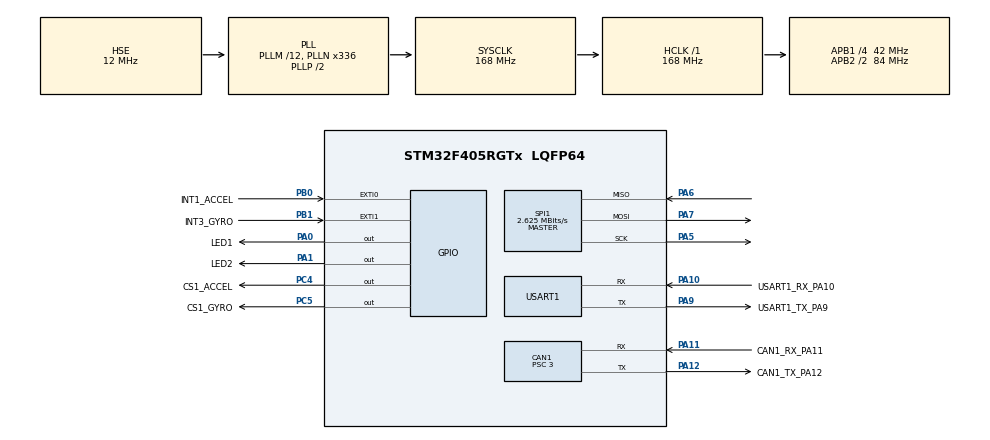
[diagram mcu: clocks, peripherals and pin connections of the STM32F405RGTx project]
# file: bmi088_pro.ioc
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ADC1.Channel-0\#ChannelRegularConversion=ADC_CHANNEL_TEMPSENSOR
ADC1.NbrOfConversionFlag=1
ADC1.Rank-0\#ChannelRegularConversion=1
ADC1.SamplingTime-0\#ChannelRegularConversion=ADC_SAMPLETIME_3CYCLES
ADC1.master=1
CAN1.BS1=CAN_BS1_10TQ
CAN1.BS2=CAN_BS2_3TQ
CAN1.CalculateTimeQuantum=71.42857142857143
CAN1.Prescaler=3
FREERTOS.Tasks01=defaultTask,0,128,StartDefaultTask,Default,NULL,Dynamic,NULL,NULL
Mcu.Family=STM32F4
Mcu.Name=STM32F405RGTx
Mcu.Package=LQFP64
NVIC.EXTI0_IRQn=true\:5\:0\:false\:false\:true\:true\:true\:true
NVIC.EXTI1_IRQn=true\:5\:0\:false\:false\:true\:true\:true\:true
NVIC.PriorityGroup=NVIC_PRIORITYGROUP_4
NVIC.USART1_IRQn=true\:5\:0\:false\:false\:true\:true\:true\:true
PA0-WKUP.GPIO_Label=LED1
PA0-WKUP.Signal=GPIO_Output
PA1.GPIO_Label=LED2
PA1.Signal=GPIO_Output
PA10.GPIO_Label=USART1_RX_PA10
PA10.Mode=Asynchronous
PA10.Signal=USART1_RX
PA11.GPIO_Label=CAN1_RX_PA11
PA11.Mode=Master
PA11.Signal=CAN1_RX
PA12.GPIO_Label=CAN1_TX_PA12
PA12.Mode=Master
PA12.Signal=CAN1_TX
PA13.Mode=Serial_Wire
PA13.Signal=SYS_JTMS-SWDIO
PA14.Mode=Serial_Wire
PA14.Signal=SYS_JTCK-SWCLK
PA5.Mode=Full_Duplex_Master
PA5.Signal=SPI1_SCK
PA6.Mode=Full_Duplex_Master
PA6.Signal=SPI1_MISO
PA7.Mode=Full_Duplex_Master
PA7.Signal=SPI1_MOSI
PA9.GPIO_Label=USART1_TX_PA9
PA9.Mode=Asynchronous
PA9.Signal=USART1_TX
PB0.GPIO_Label=INT1_ACCEL
PB0.Signal=GPXTI0
PB1.GPIO_Label=INT3_GYRO
PB1.Signal=GPXTI1
PC4.GPIO_Label=CS1_ACCEL
PC4.Signal=GPIO_Output
PC5.GPIO_Label=CS1_GYRO
PC5.Signal=GPIO_Output
PH0-OSC_IN.Mode=HSE-External-Oscillator
PH0-OSC_IN.Signal=RCC_OSC_IN
PH1-OSC_OUT.Mode=HSE-External-Oscillator
PH1-OSC_OUT.Signal=RCC_OSC_OUT
ProjectManager.HeapSize=0x200
ProjectManager.StackSize=0x400
ProjectManager.TargetToolchain=MDK-ARM V5.27
RCC.48MHZClocksFreq_Value=84000000
RCC.AHBFreq_Value=168000000
RCC.APB1CLKDivider=RCC_HCLK_DIV4
RCC.APB1Freq_Value=42000000
RCC.APB1TimFreq_Value=84000000
RCC.APB2CLKDivider=RCC_HCLK_DIV2
RCC.APB2Freq_Value=84000000
RCC.APB2TimFreq_Value=168000000
RCC.CortexFreq_Value=168000000
RCC.HCLKFreq_Value=168000000
RCC.HSE_VALUE=12000000
RCC.HSI_VALUE=16000000
RCC.LSE_VALUE=32768
RCC.PLLM=12
RCC.PLLN=336
RCC.PLLSourceVirtual=RCC_PLLSOURCE_HSE
RCC.SYSCLKFreq_VALUE=168000000
RCC.SYSCLKSource=RCC_SYSCLKSOURCE_PLLCLK
RCC.VCOOutputFreq_Value=336000000
SPI1.BaudRatePrescaler=SPI_BAUDRATEPRESCALER_32
SPI1.CLKPhase=SPI_PHASE_1EDGE
SPI1.CLKPolarity=SPI_POLARITY_LOW
SPI1.CalculateBaudRate=2.625 MBits/s
SPI1.Direction=SPI_DIRECTION_2LINES
SPI1.Mode=SPI_MODE_MASTER
SPI1.VirtualType=VM_MASTER
USART1.VirtualMode=VM_ASYNC
VP_ADC1_TempSens_Input.Mode=IN-TempSens
VP_ADC1_Vref_Input.Mode=IN-Vrefint
VP_FREERTOS_VS_CMSIS_V1.Mode=CMSIS_V1
board=custom

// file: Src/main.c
/* USER CODE BEGIN Header */
/**
  ******************************************************************************
  * @file           : main.c
  * @brief          : Main program body
  ******************************************************************************
  * @attention
  *
  * <h2><center>&copy; Copyright (c) 2020 STMicroelectronics.
  * All rights reserved.</center></h2>
  *
  * This software component is licensed by ST under Ultimate Liberty license
  * SLA0044, the "License"; You may not use this file except in compliance with
  * the License. You may obtain a copy of the License at:
  *                             www.st.com/SLA0044
  *
  ******************************************************************************
  */
/* USER CODE END Header */

#include "main.h"
#include "cmsis_os.h"
#include "adc.h"
#include "can.h"
#include "spi.h"
#include "usart.h"
#include "gpio.h"

/* USER CODE BEGIN Includes */
#include "bmi08x.h"
#include "bmi088.h"
#include "bmi088_stm32.h"
/* USER CODE END Includes */

void SystemClock_Config(void);
void MX_FREERTOS_Init(void);

/* USER CODE BEGIN 0 */
struct bmi08x_dev dev = {
		.gpio_acc_port = CS1_ACCEL_GPIO_Port,
		.gpio_gyro_port = CS1_GYRO_GPIO_Port,
        .accel_id = CS1_ACCEL_Pin,
        .gyro_id = CS1_GYRO_Pin,
        .intf = BMI08X_SPI_INTF,
        .read = &stm32_spi_read,//user_spi_read
        .write = &stm32_spi_write,//user_spi_write
        .delay_ms = &HAL_Delay//user_delay_milli_sec
		//.accel_cfg.odr = BMI08X_ACCEL_ODR_400_HZ,
		//.accel_cfg.bw = BMI08X_ACCEL_BW_NORMAL,
		//.accel_cfg.range = BMI088_ACCEL_RANGE_3G
};

struct bmi08x_int_cfg int_config;
struct bmi08x_data_sync_cfg sync_cfg;
int8_t rslt;
struct bmi08x_sensor_data user_accel_bmi088;
struct bmi08x_sensor_data user_gyro_bmi088;
uint8_t data = 0;
int count2=0;
int init_flag=0;
/* USER CODE END 0 */

int main(void)
{

  /* MCU Configuration--------------------------------------------------------*/

  /* Reset of all peripherals, Initializes the Flash interface and the Systick. */
  HAL_Init();

  /* Configure the system clock */
  SystemClock_Config();

  /* Initialize all configured peripherals */
  MX_GPIO_Init();
  MX_ADC1_Init();
  MX_CAN1_Init();
  MX_SPI1_Init();
  MX_USART1_UART_Init();
  /* USER CODE BEGIN 2 */

  /* Initialize bmi088 sensors (accel & gyro)*/
  rslt = bmi088_init(&dev);
  /* Reset the accelerometer and wait for 1 ms - delay taken care inside the function */
  rslt = bmi08a_soft_reset(&dev);

  /*! Max read/write length (maximum supported length is 32).
   To be set by the user */
  dev.read_write_len = 32;
  /*set accel power mode */
  dev.accel_cfg.power = BMI08X_ACCEL_PM_ACTIVE;
  rslt = bmi08a_set_power_mode(&dev);

  dev.gyro_cfg.power = BMI08X_GYRO_PM_NORMAL;
  bmi08g_set_power_mode(&dev);

  /* API uploads the bmi08x config file onto the device and wait for 150ms
     to enable the data synchronization - delay taken care inside the function */
  rslt = bmi088_apply_config_file(&dev);

  /*assign accel range setting*/
  dev.accel_cfg.range = BMI088_ACCEL_RANGE_3G;
  /*assign gyro range setting*/
  dev.gyro_cfg.range = BMI08X_GYRO_RANGE_2000_DPS;
  /*! Mode (0 = off, 1 = 400Hz, 2 = 1kHz, 3 = 2kHz) */
  sync_cfg.mode = BMI08X_ACCEL_DATA_SYNC_MODE_2000HZ;
  rslt = bmi088_configure_data_synchronization(sync_cfg, &dev);

  /*set accel interrupt pin configuration*/
  /*configure host data ready interrupt */
  int_config.accel_int_config_1.int_channel = BMI08X_INT_CHANNEL_1;
  int_config.accel_int_config_1.int_type = BMI08X_ACCEL_SYNC_INPUT;
  int_config.accel_int_config_1.int_pin_cfg.output_mode = BMI08X_INT_MODE_PUSH_PULL;
  int_config.accel_int_config_1.int_pin_cfg.lvl = BMI08X_INT_ACTIVE_HIGH;
  int_config.accel_int_config_1.int_pin_cfg.enable_int_pin = BMI08X_ENABLE;

  /*configure Accel syncronization input interrupt pin */
  int_config.accel_int_config_2.int_channel = BMI08X_INT_CHANNEL_2;
  int_config.accel_int_config_2.int_type = BMI08X_ACCEL_SYNC_DATA_RDY_INT;
  int_config.accel_int_config_2.int_pin_cfg.output_mode = BMI08X_INT_MODE_PUSH_PULL;
  int_config.accel_int_config_2.int_pin_cfg.lvl = BMI08X_INT_ACTIVE_HIGH;
  int_config.accel_int_config_2.int_pin_cfg.enable_int_pin = BMI08X_ENABLE;

  /*set gyro interrupt pin configuration*/
  int_config.gyro_int_config_1.int_channel = BMI08X_INT_CHANNEL_3;
  int_config.gyro_int_config_1.int_type = BMI08X_GYRO_DATA_RDY_INT;
  int_config.gyro_int_config_1.int_pin_cfg.enable_int_pin = BMI08X_ENABLE;
  int_config.gyro_int_config_1.int_pin_cfg.lvl = BMI08X_INT_ACTIVE_HIGH;
  int_config.gyro_int_config_1.int_pin_cfg.output_mode = BMI08X_INT_MODE_PUSH_PULL;

  int_config.gyro_int_config_2.int_channel = BMI08X_INT_CHANNEL_4;
  int_config.gyro_int_config_2.int_type = BMI08X_GYRO_DATA_RDY_INT;
  int_config.gyro_int_config_2.int_pin_cfg.enable_int_pin = BMI08X_DISABLE;
  int_config.gyro_int_config_2.int_pin_cfg.lvl = BMI08X_INT_ACTIVE_HIGH;
  int_config.gyro_int_config_2.int_pin_cfg.output_mode = BMI08X_INT_MODE_PUSH_PULL;

  /* Enable synchronization interrupt pin */
  rslt = bmi088_set_data_sync_int_config(&int_config, &dev);

  init_flag=1;
  /* USER CODE END 2 */

  /* Call init function for freertos objects (in freertos.c) */
  MX_FREERTOS_Init();

  /* Start scheduler */
  osKernelStart();

  /* We should never get here as control is now taken by the scheduler */

  /* Infinite loop */
  while (1)
  {

  }
}

void SystemClock_Config(void)
{
  RCC_OscInitTypeDef RCC_OscInitStruct = {0};
  RCC_ClkInitTypeDef RCC_ClkInitStruct = {0};

  /** Configure the main internal regulator output voltage
  */
  __HAL_RCC_PWR_CLK_ENABLE();
  __HAL_PWR_VOLTAGESCALING_CONFIG(PWR_REGULATOR_VOLTAGE_SCALE1);
  /** Initializes the CPU, AHB and APB busses clocks
  */
  RCC_OscInitStruct.OscillatorType = RCC_OSCILLATORTYPE_HSE;
  RCC_OscInitStruct.HSEState = RCC_HSE_ON;
  RCC_OscInitStruct.PLL.PLLState = RCC_PLL_ON;
  RCC_OscInitStruct.PLL.PLLSource = RCC_PLLSOURCE_HSE;
  RCC_OscInitStruct.PLL.PLLM = 12;
  RCC_OscInitStruct.PLL.PLLN = 336;
  RCC_OscInitStruct.PLL.PLLP = RCC_PLLP_DIV2;
  RCC_OscInitStruct.PLL.PLLQ = 4;
  if (HAL_RCC_OscConfig(&RCC_OscInitStruct) != HAL_OK)
  {
    Error_Handler();
  }
  /** Initializes the CPU, AHB and APB busses clocks
  */
  RCC_ClkInitStruct.ClockType = RCC_CLOCKTYPE_HCLK|RCC_CLOCKTYPE_SYSCLK
                              |RCC_CLOCKTYPE_PCLK1|RCC_CLOCKTYPE_PCLK2;
  RCC_ClkInitStruct.SYSCLKSource = RCC_SYSCLKSOURCE_PLLCLK;
  RCC_ClkInitStruct.AHBCLKDivider = RCC_SYSCLK_DIV1;
  RCC_ClkInitStruct.APB1CLKDivider = RCC_HCLK_DIV4;
  RCC_ClkInitStruct.APB2CLKDivider = RCC_HCLK_DIV2;

  if (HAL_RCC_ClockConfig(&RCC_ClkInitStruct, FLASH_LATENCY_5) != HAL_OK)
  {
    Error_Handler();
  }
}

void Error_Handler(void)
{
}

/************************ (C) COPYRIGHT STMicroelectronics *****END OF FILE****/

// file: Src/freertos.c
/* USER CODE BEGIN Header */
/**
  ******************************************************************************
  * File Name          : freertos.c
  * Description        : Code for freertos applications
  ******************************************************************************
  * @attention
  *
  * <h2><center>&copy; Copyright (c) 2020 STMicroelectronics.
  * All rights reserved.</center></h2>
  *
  * This software component is licensed by ST under Ultimate Liberty license
  * SLA0044, the "License"; You may not use this file except in compliance with
  * the License. You may obtain a copy of the License at:
  *                             www.st.com/SLA0044
  *
  ******************************************************************************
  */
/* USER CODE END Header */

#include "FreeRTOS.h"
#include "task.h"
#include "main.h"
#include "cmsis_os.h"

osThreadId defaultTaskHandle;

void StartDefaultTask(void const * argument);

void MX_FREERTOS_Init(void); /* (MISRA C 2004 rule 8.1) */

/* GetIdleTaskMemory prototype (linked to static allocation support) */
void vApplicationGetIdleTaskMemory( StaticTask_t **ppxIdleTaskTCBBuffer, StackType_t **ppxIdleTaskStackBuffer, uint32_t *pulIdleTaskStackSize );

/* USER CODE BEGIN GET_IDLE_TASK_MEMORY */
static StaticTask_t xIdleTaskTCBBuffer;
static StackType_t xIdleStack[configMINIMAL_STACK_SIZE];

void vApplicationGetIdleTaskMemory( StaticTask_t **ppxIdleTaskTCBBuffer, StackType_t **ppxIdleTaskStackBuffer, uint32_t *pulIdleTaskStackSize )
{
  *ppxIdleTaskTCBBuffer = &xIdleTaskTCBBuffer;
  *ppxIdleTaskStackBuffer = &xIdleStack[0];
  *pulIdleTaskStackSize = configMINIMAL_STACK_SIZE;
  /* place for user code */
}
/* USER CODE END GET_IDLE_TASK_MEMORY */

void MX_FREERTOS_Init(void) {

  /* Create the thread(s) */
  /* definition and creation of defaultTask */
  osThreadDef(defaultTask, StartDefaultTask, osPriorityNormal, 0, 128);
  defaultTaskHandle = osThreadCreate(osThread(defaultTask), NULL);

}

void StartDefaultTask(void const * argument)
{
  for(;;)
  {
    osDelay(1);
  }
}

/************************ (C) COPYRIGHT STMicroelectronics *****END OF FILE****/
